# STM32MP157 register map
File version: 1.6
CPU: CM4 r0p1, little endian, no MPU, FPU, 4 interrupt priority bits
Registers are 32-bit, read-write, reset 0x0 unless marked. A register's access mark holds for its fields unless they carry their own. Offsets are from the block's base; [hi:lo] are bit positions; lines under a group give offsets from that group; {n}, {i} and the like mark numbered series.

## DFSDM1
Base 0x4400D000
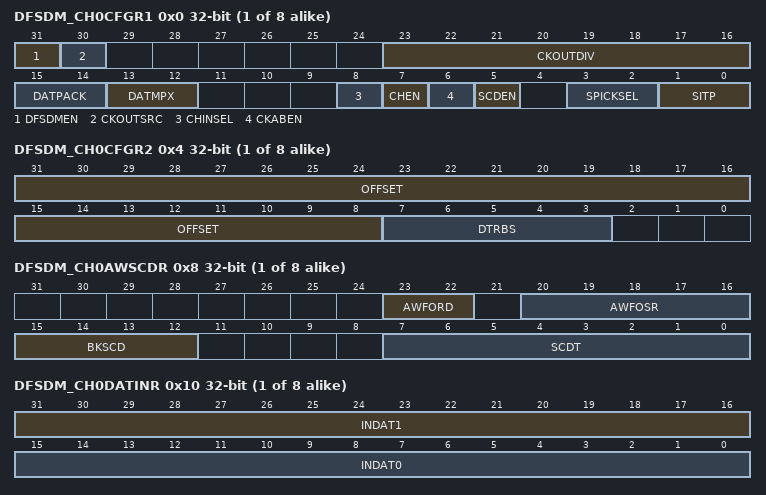
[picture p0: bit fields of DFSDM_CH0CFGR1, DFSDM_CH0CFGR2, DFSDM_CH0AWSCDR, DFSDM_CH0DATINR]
{0x0+0x20*i} DFSDM_CH{i}CFGR1 (i=0..7) — This register specifies the parameters used by channel y.
  [31] DFSDMEN, [30] CKOUTSRC, [23:16] CKOUTDIV, [15:14] DATPACK, [13:12] DATMPX, [8] CHINSEL, [7] CHEN, [6] CKABEN, [5] SCDEN, [3:2] SPICKSEL, [1:0] SITP
{0x4+0x20*i} DFSDM_CH{i}CFGR2 (i=0..7) — This register specifies the parameters used by channel y.
  [31:8] OFFSET, [7:3] DTRBS
{0x8+0x20*i} DFSDM_CH{i}AWSCDR (i=0..7) — Short-circuit detector and analog watchdog settings for channel y.
  [23:22] AWFORD, [20:16] AWFOSR, [15:12] BKSCD, [7:0] SCDT
{0xC+0x20*i} DFSDM_CH{i}WDATR ro (i=0..7) — This register contains the data resulting from the analog watchdog filter associated to the input channel y.
  [15:0] WDATA
{0x10+0x20*i} DFSDM_CH{i}DATINR (i=0..7) — This register contains 16-bit input data to be processed by DFSDM filter module.
  [31:16] INDAT1, [15:0] INDAT0
{0x14+0x20*i} DFSDM_CH{i}DLYR (i=0..7) — DFSDM channel {i} delay register
  [5:0] PLSSKP
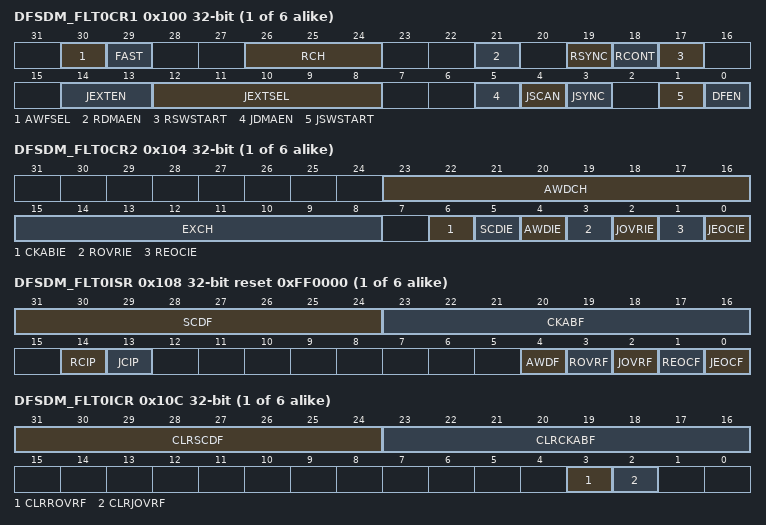
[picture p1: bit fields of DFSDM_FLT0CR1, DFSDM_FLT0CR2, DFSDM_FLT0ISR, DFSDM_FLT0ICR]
{0x100+0x80*i} DFSDM_FLT{i}CR1 (i=0..5) — DFSDM filter {i} control register 1
  [30] AWFSEL, [29] FAST, [26:24] RCH, [21] RDMAEN, [19] RSYNC, [18] RCONT, [17] RSWSTART, [14:13] JEXTEN, [12:8] JEXTSEL, [5] JDMAEN, [4] JSCAN, [3] JSYNC, [1] JSWSTART, [0] DFEN
{0x104+0x80*i} DFSDM_FLT{i}CR2 (i=0..5) — DFSDM filter {i} control register 2
  [23:16] AWDCH, [15:8] EXCH, [6] CKABIE, [5] SCDIE, [4] AWDIE, [3] ROVRIE, [2] JOVRIE, [1] REOCIE, [0] JEOCIE
{0x108+0x80*i} DFSDM_FLT{i}ISR ro reset 0xFF0000 (i=0..5) — DFSDM filter {i} interrupt and status register
  [31:24] SCDF, [23:16] CKABF, [14] RCIP, [13] JCIP, [4] AWDF, [3] ROVRF, [2] JOVRF, [1] REOCF, [0] JEOCF
{0x10C+0x80*i} DFSDM_FLT{i}ICR (i=0..5) — DFSDM filter {i} interrupt flag clear register
  [31:24] CLRSCDF, [23:16] CLRCKABF, [3] CLRROVRF, [2] CLRJOVRF
{0x110+0x80*i} DFSDM_FLT{i}JCHGR reset 0x1 (i=0..5) — DFSDM filter {i} injected channel group selection register
  [7:0] JCHG
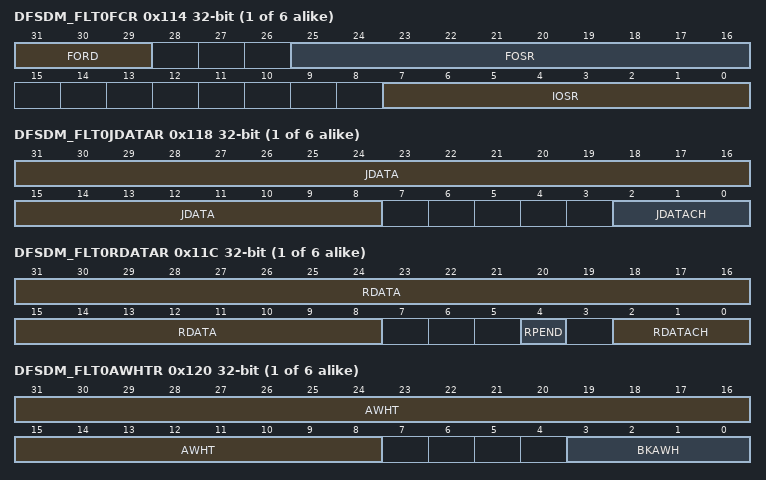
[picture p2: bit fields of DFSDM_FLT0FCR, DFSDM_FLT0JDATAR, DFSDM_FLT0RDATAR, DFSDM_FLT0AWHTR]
{0x114+0x80*i} DFSDM_FLT{i}FCR (i=0..5) — DFSDM filter {i} control register
  [31:29] FORD, [25:16] FOSR, [7:0] IOSR
{0x118+0x80*i} DFSDM_FLT{i}JDATAR ro (i=0..5) — DFSDM filter {i} data register for injected group
  [31:8] JDATA, [2:0] JDATACH
{0x11C+0x80*i} DFSDM_FLT{i}RDATAR ro (i=0..5) — DFSDM filter {i} data register for the regular channel
  [31:8] RDATA, [4] RPEND, [2:0] RDATACH
{0x120+0x80*i} DFSDM_FLT{i}AWHTR (i=0..5) — DFSDM filter {i} analog watchdog high threshold register
  [31:8] AWHT, [3:0] BKAWH
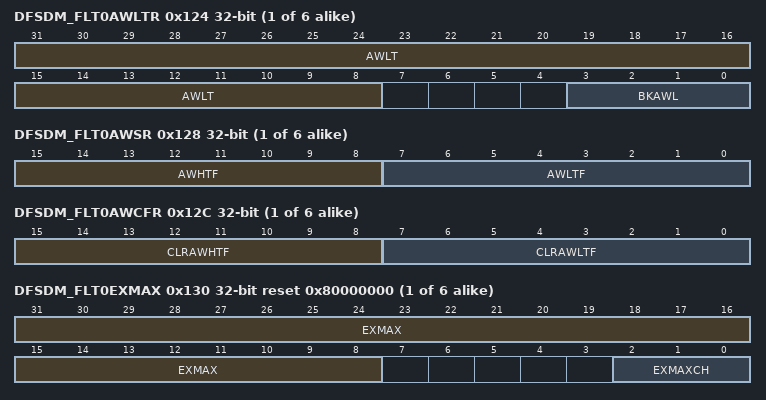
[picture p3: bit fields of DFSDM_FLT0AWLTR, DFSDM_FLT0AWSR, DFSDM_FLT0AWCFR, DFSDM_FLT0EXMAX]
{0x124+0x80*i} DFSDM_FLT{i}AWLTR (i=0..5) — DFSDM filter {i} analog watchdog low threshold register
  [31:8] AWLT, [3:0] BKAWL
{0x128+0x80*i} DFSDM_FLT{i}AWSR ro (i=0..5) — DFSDM filter {i} analog watchdog status register
  [15:8] AWHTF, [7:0] AWLTF
{0x12C+0x80*i} DFSDM_FLT{i}AWCFR (i=0..5) — DFSDM filter {i} analog watchdog clear flag register
  [15:8] CLRAWHTF, [7:0] CLRAWLTF
{0x130+0x80*i} DFSDM_FLT{i}EXMAX ro reset 0x80000000 (i=0..5) — DFSDM filter {i} extremes detector maximum register
  [31:8] EXMAX, [2:0] EXMAXCH
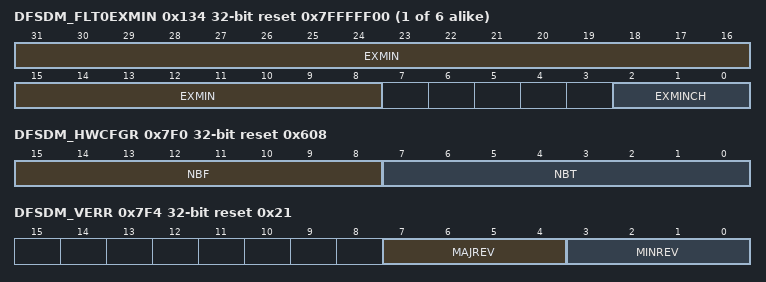
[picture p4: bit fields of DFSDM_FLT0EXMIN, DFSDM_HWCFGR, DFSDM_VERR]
{0x134+0x80*i} DFSDM_FLT{i}EXMIN access per field reset 0x7FFFFF00 (i=0..5) — DFSDM filter {i} extremes detector minimum register
  [31:8] EXMIN rw, [2:0] EXMINCH ro
{0x138+0x80*i} DFSDM_FLT{i}CNVTIMR ro (i=0..5) — DFSDM filter {i} conversion timer register
  [31:4] CNVCNT
0x7F0 DFSDM_HWCFGR ro reset 0x608 — This register specifies the hardware configuration of DFSDM peripheral.
  [15:8] NBF, [7:0] NBT
0x7F4 DFSDM_VERR ro reset 0x21 — This register specifies the version of DFSDM peripheral.
  [7:4] MAJREV, [3:0] MINREV
0x7F8 DFSDM_IPIDR ro reset 0x110031 — This register specifies the identification of DFSDM peripheral.
  [31:0] ID
0x7FC DFSDM_SIDR ro reset 0xA3C5DD02 — This register specifies the size allocated to DFSDM registers.
  [31:0] SID
